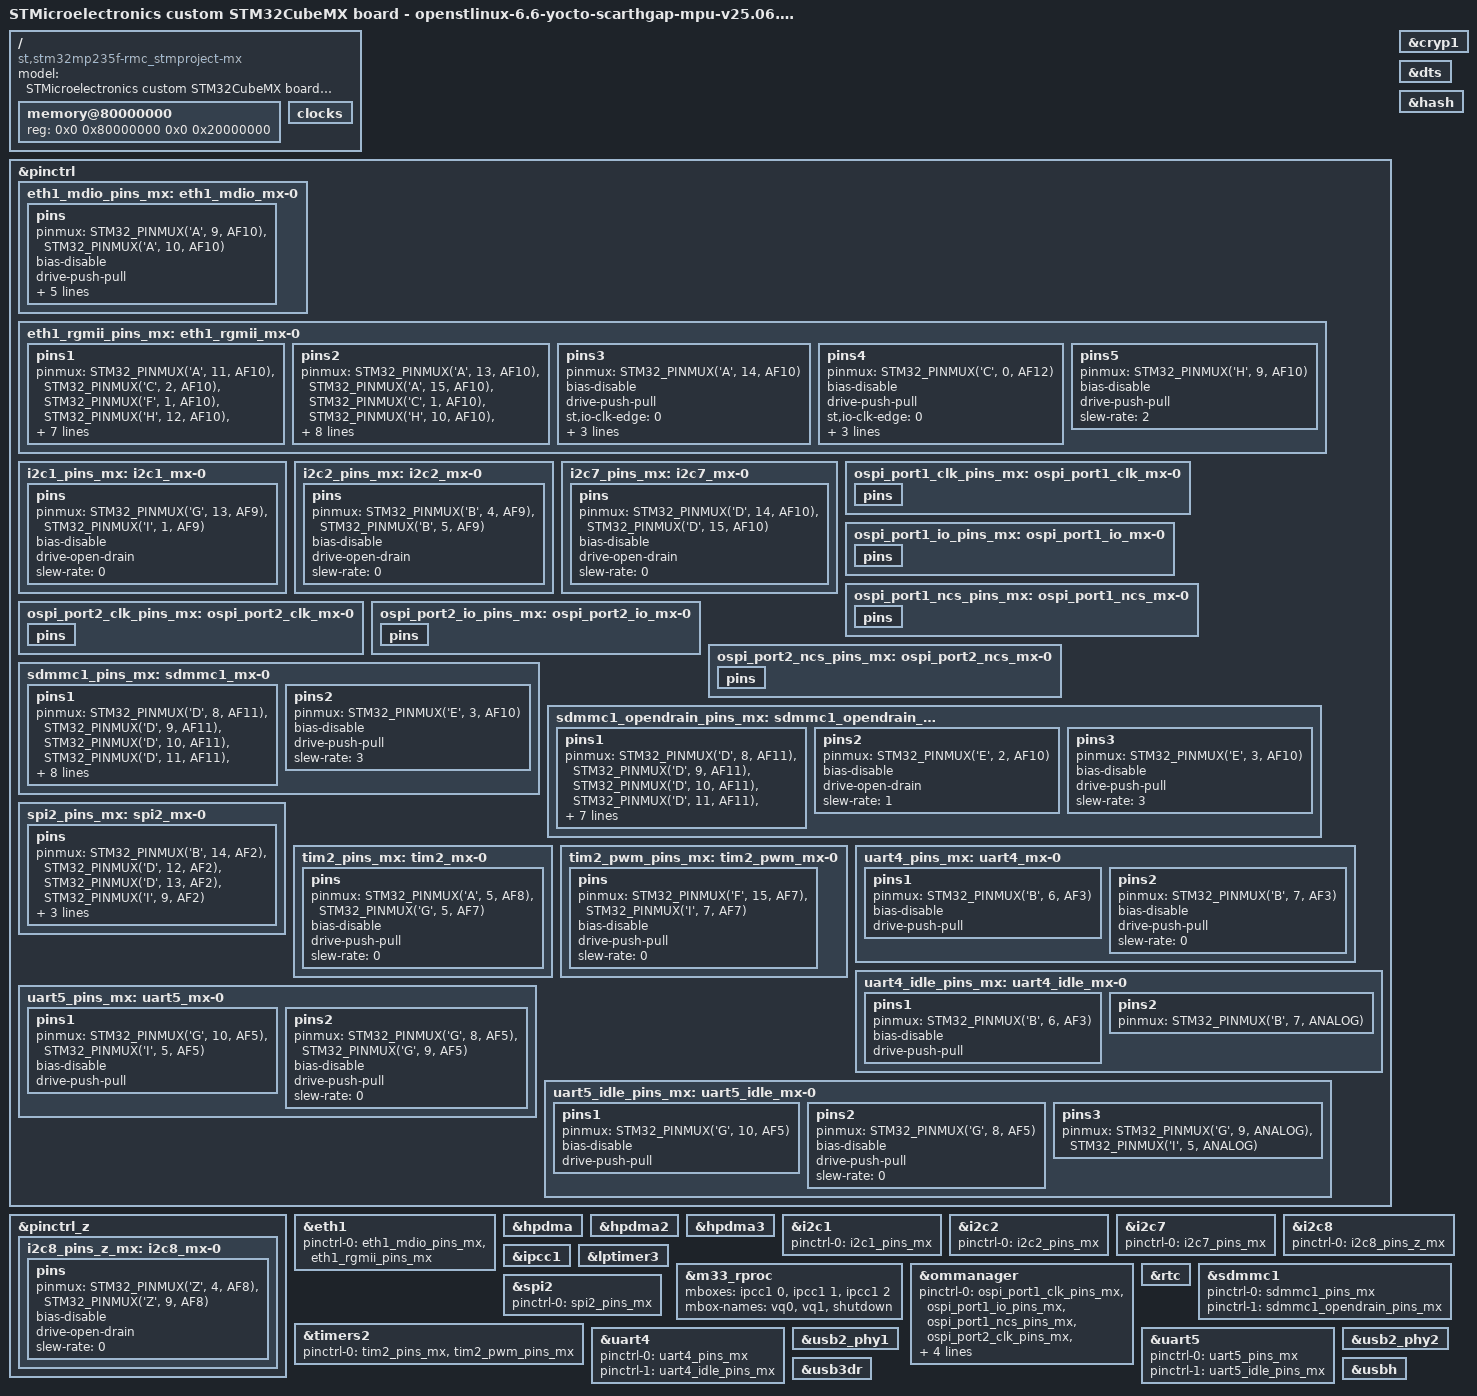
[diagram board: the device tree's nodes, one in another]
// SPDX-License-Identifier: (GPL-2.0-only OR BSD-3-Clause)
/*
 * Copyright (C) 2026, STMicroelectronics - All Rights Reserved
 * Author: STM32CubeMX code generation for STMicroelectronics.
 */

/* For more information on Device Tree configuration, please refer to
 * https://wiki.st.com/stm32mpu/wiki/Category:Device_tree_configuration
 */

/dts-v1/;

#include <dt-bindings/pinctrl/stm32-pinfunc.h>
#include "stm32mp235.dtsi"
#include "stm32mp23xf.dtsi"
#include "stm32mp235f-rmc_stmproject-mx-resmem.dtsi"
#include "stm32mp25xxal-pinctrl.dtsi"

/* USER CODE BEGIN includes */
/* USER CODE END includes */

/ {
	model = "STMicroelectronics custom STM32CubeMX board - openstlinux-6.6-yocto-scarthgap-mpu-v25.06.11";
	compatible = "st,stm32mp235f-rmc_stmproject-mx", "st,stm32mp235";

	memory@80000000 {
		device_type = "memory";
		reg = <0x0 0x80000000 0x0 0x20000000>;

		/* USER CODE BEGIN memory */
		/* USER CODE END memory */
	};

	/* USER CODE BEGIN root */
	/* USER CODE END root */

	clocks{

		/* USER CODE BEGIN clocks */
		/* USER CODE END clocks */
	};

}; /*root*/

&pinctrl {

	eth1_mdio_pins_mx: eth1_mdio_mx-0 {
		pins {
			pinmux = <STM32_PINMUX('A', 9, AF10)>, /* ETH1_MDC */
					 <STM32_PINMUX('A', 10, AF10)>; /* ETH1_MDIO */
			bias-disable;
			drive-push-pull;
			slew-rate = <1>;
			st,io-clk-edge = <0>;
			st,io-retime = <0>;
			st,io-delay-path = <0>;
			st,io-delay = <0>;
		};
	};

	eth1_rgmii_pins_mx: eth1_rgmii_mx-0 {
		pins1 {
			pinmux = <STM32_PINMUX('A', 11, AF10)>, /* ETH1_RGMII_RX_CTL */
					 <STM32_PINMUX('C', 2, AF10)>, /* ETH1_RGMII_RXD1 */
					 <STM32_PINMUX('F', 1, AF10)>, /* ETH1_RGMII_RXD0 */
					 <STM32_PINMUX('H', 12, AF10)>, /* ETH1_RGMII_RXD2 */
					 <STM32_PINMUX('H', 13, AF10)>; /* ETH1_RGMII_RXD3 */
			bias-disable;
			drive-push-pull;
			st,io-clk-edge = <1>;
			st,io-retime = <1>;
			st,io-delay-path = <0>;
			st,io-delay = <0>;
		};
		pins2 {
			pinmux = <STM32_PINMUX('A', 13, AF10)>, /* ETH1_RGMII_TX_CTL */
					 <STM32_PINMUX('A', 15, AF10)>, /* ETH1_RGMII_TXD0 */
					 <STM32_PINMUX('C', 1, AF10)>, /* ETH1_RGMII_TXD1 */
					 <STM32_PINMUX('H', 10, AF10)>, /* ETH1_RGMII_TXD2 */
					 <STM32_PINMUX('H', 11, AF10)>; /* ETH1_RGMII_TXD3 */
			bias-disable;
			drive-push-pull;
			slew-rate = <2>;
			st,io-clk-edge = <1>;
			st,io-retime = <1>;
			st,io-delay-path = <0>;
			st,io-delay = <0>;
		};
		pins3 {
			pinmux = <STM32_PINMUX('A', 14, AF10)>; /* ETH1_RGMII_RX_CLK */
			bias-disable;
			drive-push-pull;
			st,io-clk-edge = <0>;
			st,io-retime = <0>;
			st,io-delay-path = <1>;
			st,io-delay = <0>;
		};
		pins4 {
			pinmux = <STM32_PINMUX('C', 0, AF12)>; /* ETH1_RGMII_GTX_CLK */
			bias-disable;
			drive-push-pull;
			st,io-clk-edge = <0>;
			st,io-retime = <0>;
			st,io-delay-path = <0>;
			st,io-delay = <0>;
		};
		pins5 {
			pinmux = <STM32_PINMUX('H', 9, AF10)>; /* ETH1_RGMII_CLK125 */
			bias-disable;
			drive-push-pull;
			slew-rate = <2>;
		};
	};

	i2c1_pins_mx: i2c1_mx-0 {
		pins {
			pinmux = <STM32_PINMUX('G', 13, AF9)>, /* I2C1_SCL */
					 <STM32_PINMUX('I', 1, AF9)>; /* I2C1_SDA */
			bias-disable;
			drive-open-drain;
			slew-rate = <0>;
		};
	};

	i2c2_pins_mx: i2c2_mx-0 {
		pins {
			pinmux = <STM32_PINMUX('B', 4, AF9)>, /* I2C2_SDA */
					 <STM32_PINMUX('B', 5, AF9)>; /* I2C2_SCL */
			bias-disable;
			drive-open-drain;
			slew-rate = <0>;
		};
	};

	i2c7_pins_mx: i2c7_mx-0 {
		pins {
			pinmux = <STM32_PINMUX('D', 14, AF10)>, /* I2C7_SDA */
					 <STM32_PINMUX('D', 15, AF10)>; /* I2C7_SCL */
			bias-disable;
			drive-open-drain;
			slew-rate = <0>;
		};
	};

	ospi_port1_clk_pins_mx: ospi_port1_clk_mx-0 {
		pins {
		};
	};

	ospi_port1_io_pins_mx: ospi_port1_io_mx-0 {
		pins {
		};
	};

	ospi_port1_ncs_pins_mx: ospi_port1_ncs_mx-0 {
		pins {
		};
	};

	ospi_port2_clk_pins_mx: ospi_port2_clk_mx-0 {
		pins {
		};
	};

	ospi_port2_io_pins_mx: ospi_port2_io_mx-0 {
		pins {
		};
	};

	ospi_port2_ncs_pins_mx: ospi_port2_ncs_mx-0 {
		pins {
		};
	};

	sdmmc1_pins_mx: sdmmc1_mx-0 {
		pins1 {
			pinmux = <STM32_PINMUX('D', 8, AF11)>, /* SDMMC1_D7 */
					 <STM32_PINMUX('D', 9, AF11)>, /* SDMMC1_D6 */
					 <STM32_PINMUX('D', 10, AF11)>, /* SDMMC1_D5 */
					 <STM32_PINMUX('D', 11, AF11)>, /* SDMMC1_D4 */
					 <STM32_PINMUX('E', 0, AF10)>, /* SDMMC1_D2 */
					 <STM32_PINMUX('E', 1, AF10)>, /* SDMMC1_D3 */
					 <STM32_PINMUX('E', 2, AF10)>, /* SDMMC1_CMD */
					 <STM32_PINMUX('E', 4, AF10)>, /* SDMMC1_D0 */
					 <STM32_PINMUX('E', 5, AF10)>; /* SDMMC1_D1 */
			bias-disable;
			drive-push-pull;
			slew-rate = <1>;
		};
		pins2 {
			pinmux = <STM32_PINMUX('E', 3, AF10)>; /* SDMMC1_CK */
			bias-disable;
			drive-push-pull;
			slew-rate = <3>;
		};
	};

	sdmmc1_opendrain_pins_mx: sdmmc1_opendrain_mx-0 {
		pins1 {
			pinmux = <STM32_PINMUX('D', 8, AF11)>, /* SDMMC1_D7 */
					 <STM32_PINMUX('D', 9, AF11)>, /* SDMMC1_D6 */
					 <STM32_PINMUX('D', 10, AF11)>, /* SDMMC1_D5 */
					 <STM32_PINMUX('D', 11, AF11)>, /* SDMMC1_D4 */
					 <STM32_PINMUX('E', 0, AF10)>, /* SDMMC1_D2 */
					 <STM32_PINMUX('E', 1, AF10)>, /* SDMMC1_D3 */
					 <STM32_PINMUX('E', 4, AF10)>, /* SDMMC1_D0 */
					 <STM32_PINMUX('E', 5, AF10)>; /* SDMMC1_D1 */
			bias-disable;
			drive-push-pull;
			slew-rate = <1>;
		};
		pins2 {
			pinmux = <STM32_PINMUX('E', 2, AF10)>; /* SDMMC1_CMD */
			bias-disable;
			drive-open-drain;
			slew-rate = <1>;
		};
		pins3 {
			pinmux = <STM32_PINMUX('E', 3, AF10)>; /* SDMMC1_CK */
			bias-disable;
			drive-push-pull;
			slew-rate = <3>;
		};
	};

	spi2_pins_mx: spi2_mx-0 {
		pins {
			pinmux = <STM32_PINMUX('B', 14, AF2)>, /* SPI2_SCK */
					 <STM32_PINMUX('D', 12, AF2)>, /* SPI2_MISO */
					 <STM32_PINMUX('D', 13, AF2)>, /* SPI2_NSS */
					 <STM32_PINMUX('I', 9, AF2)>; /* SPI2_MOSI */
			bias-disable;
			drive-push-pull;
			slew-rate = <0>;
		};
	};

	tim2_pins_mx: tim2_mx-0 {
		pins {
			pinmux = <STM32_PINMUX('A', 5, AF8)>, /* TIM2_CH4 */
					 <STM32_PINMUX('G', 5, AF7)>; /* TIM2_CH3 */
			bias-disable;
			drive-push-pull;
			slew-rate = <0>;
		};
	};

	tim2_pwm_pins_mx: tim2_pwm_mx-0 {
		pins {
			pinmux = <STM32_PINMUX('F', 15, AF7)>, /* TIM2_CH2 */
					 <STM32_PINMUX('I', 7, AF7)>; /* TIM2_CH1 */
			bias-disable;
			drive-push-pull;
			slew-rate = <0>;
		};
	};

	uart4_pins_mx: uart4_mx-0 {
		pins1 {
			pinmux = <STM32_PINMUX('B', 6, AF3)>; /* UART4_RX */
			bias-disable;
			drive-push-pull;
		};
		pins2 {
			pinmux = <STM32_PINMUX('B', 7, AF3)>; /* UART4_TX */
			bias-disable;
			drive-push-pull;
			slew-rate = <0>;
		};
	};

	uart4_idle_pins_mx: uart4_idle_mx-0 {
		pins1 {
			pinmux = <STM32_PINMUX('B', 6, AF3)>; /* UART4_RX */
			bias-disable;
			drive-push-pull;
		};
		pins2 {
			pinmux = <STM32_PINMUX('B', 7, ANALOG)>; /* UART4_TX */
		};
	};

	uart5_pins_mx: uart5_mx-0 {
		pins1 {
			pinmux = <STM32_PINMUX('G', 10, AF5)>, /* UART5_RX */
					 <STM32_PINMUX('I', 5, AF5)>; /* UART5_CTS */
			bias-disable;
			drive-push-pull;
		};
		pins2 {
			pinmux = <STM32_PINMUX('G', 8, AF5)>, /* UART5_RTS */
					 <STM32_PINMUX('G', 9, AF5)>; /* UART5_TX */
			bias-disable;
			drive-push-pull;
			slew-rate = <0>;
		};
	};

	uart5_idle_pins_mx: uart5_idle_mx-0 {
		pins1 {
			pinmux = <STM32_PINMUX('G', 10, AF5)>; /* UART5_RX */
			bias-disable;
			drive-push-pull;
		};
		pins2 {
			pinmux = <STM32_PINMUX('G', 8, AF5)>; /* UART5_RTS */
			bias-disable;
			drive-push-pull;
			slew-rate = <0>;
		};
		pins3 {
			pinmux = <STM32_PINMUX('G', 9, ANALOG)>, /* UART5_TX */
					 <STM32_PINMUX('I', 5, ANALOG)>; /* UART5_CTS */
		};
	};

	/* USER CODE BEGIN pinctrl */
	/* USER CODE END pinctrl */
};

&pinctrl_z {

	i2c8_pins_z_mx: i2c8_mx-0 {
		pins {
			pinmux = <STM32_PINMUX('Z', 4, AF8)>, /* I2C8_SCL */
					 <STM32_PINMUX('Z', 9, AF8)>; /* I2C8_SDA */
			bias-disable;
			drive-open-drain;
			slew-rate = <0>;
		};
	};

	/* USER CODE BEGIN pinctrl_z */
	/* USER CODE END pinctrl_z */
};

&cryp1 {
	status = "okay";

	/* USER CODE BEGIN cryp1 */
	/* USER CODE END cryp1 */
};

&dts {
	status = "okay";

	/* USER CODE BEGIN dts */
	/* USER CODE END dts */
};

&eth1 {
	pinctrl-names = "default";
	pinctrl-0 = <&eth1_mdio_pins_mx>, <&eth1_rgmii_pins_mx>;
	status = "okay";

	/* USER CODE BEGIN eth1 */
	/* USER CODE END eth1 */
};

&hash {
	status = "okay";

	/* USER CODE BEGIN hash */
	/* USER CODE END hash */
};

&hpdma {
	status = "okay";

	/* USER CODE BEGIN hpdma */
	/* USER CODE END hpdma */
};

&hpdma2 {
	status = "okay";

	/* USER CODE BEGIN hpdma2 */
	/* USER CODE END hpdma2 */
};

&hpdma3 {
	status = "okay";

	/* USER CODE BEGIN hpdma3 */
	/* USER CODE END hpdma3 */
};

&i2c1 {
	pinctrl-names = "default";
	pinctrl-0 = <&i2c1_pins_mx>;
	status = "okay";

	/* USER CODE BEGIN i2c1 */
	/* USER CODE END i2c1 */
};

&i2c2 {
	pinctrl-names = "default";
	pinctrl-0 = <&i2c2_pins_mx>;
	status = "okay";

	/* USER CODE BEGIN i2c2 */
	/* USER CODE END i2c2 */
};

&i2c7 {
	pinctrl-names = "default";
	pinctrl-0 = <&i2c7_pins_mx>;
	status = "okay";

	/* USER CODE BEGIN i2c7 */
	/* USER CODE END i2c7 */
};

&i2c8 {
	pinctrl-names = "default";
	pinctrl-0 = <&i2c8_pins_z_mx>;
	status = "okay";

	/* USER CODE BEGIN i2c8 */
	/* USER CODE END i2c8 */
};

&ipcc1 {
	status = "okay";

	/* USER CODE BEGIN ipcc1 */
	/* USER CODE END ipcc1 */
};

&lptimer3 {
	status = "okay";

	/* USER CODE BEGIN lptimer3 */
	/* USER CODE END lptimer3 */
};

&m33_rproc {
	status = "okay";

	/*Restriction: "memory-region" property is not managed - please to use User-Section if needed*/
	mboxes = <&ipcc1 0>, <&ipcc1 1>, <&ipcc1 2>;
	mbox-names = "vq0", "vq1", "shutdown";

	/* USER CODE BEGIN m33_rproc */
	/* USER CODE END m33_rproc */
};

&ommanager {
	pinctrl-names = "default";
	pinctrl-0 = <&ospi_port1_clk_pins_mx>, <&ospi_port1_io_pins_mx>, <&ospi_port1_ncs_pins_mx>, <&ospi_port2_clk_pins_mx>, <&ospi_port2_io_pins_mx>, <&ospi_port2_ncs_pins_mx>;
	status = "okay";
	memory-region = <&mm_ospi1>, <&mm_ospi2>;
	memory-region-names = "mm_ospi1, mm_ospi2";

	/* USER CODE BEGIN ommanager */
	/* USER CODE END ommanager */
};

&rtc {
	status = "okay";

	/* USER CODE BEGIN rtc */
	/* USER CODE END rtc */
};

&sdmmc1 {
	pinctrl-names = "default", "opendrain";
	pinctrl-0 = <&sdmmc1_pins_mx>;
	pinctrl-1 = <&sdmmc1_opendrain_pins_mx>;
	status = "okay";

	/* USER CODE BEGIN sdmmc1 */
	/* USER CODE END sdmmc1 */
};

&spi2 {
	pinctrl-names = "default";
	pinctrl-0 = <&spi2_pins_mx>;
	status = "okay";

	/* USER CODE BEGIN spi2 */
	/* USER CODE END spi2 */
};

&timers2 {
	pinctrl-names = "default";
	pinctrl-0 = <&tim2_pins_mx>, <&tim2_pwm_pins_mx>;
	status = "okay";

	/* USER CODE BEGIN timers2 */
	/* USER CODE END timers2 */
};

&uart4 {
	pinctrl-names = "default", "idle";
	pinctrl-0 = <&uart4_pins_mx>;
	pinctrl-1 = <&uart4_idle_pins_mx>;
	status = "okay";

	/* USER CODE BEGIN uart4 */
	/* USER CODE END uart4 */
};

&uart5 {
	pinctrl-names = "default", "idle";
	pinctrl-0 = <&uart5_pins_mx>;
	pinctrl-1 = <&uart5_idle_pins_mx>;
	status = "okay";

	/* USER CODE BEGIN uart5 */
	/* USER CODE END uart5 */
};

&usb2_phy1 {
	status = "okay";

	/* USER CODE BEGIN usb2_phy1 */
	/* USER CODE END usb2_phy1 */
};

&usb2_phy2 {
	status = "okay";

	/* USER CODE BEGIN usb2_phy2 */
	/* USER CODE END usb2_phy2 */
};

&usb3dr {
	status = "okay";

	/* USER CODE BEGIN usb3dr */
	/* USER CODE END usb3dr */
};

&usbh {
	status = "okay";

	/* USER CODE BEGIN usbh */
	/* USER CODE END usbh */
};

/* USER CODE BEGIN addons */
/* USER CODE END addons */

